# PLL0_CFG register map
Vendor: Texas Instruments
Peripheral module from a debugger description file (folder J7VCL).
Registers are 32-bit, access per field, reset 0x0 unless marked. A register's access mark holds for its fields unless they carry their own. Offsets are as the file gives them; lines under a group give offsets from that group; [hi:lo] are bit positions; {n}, {i} and the like mark numbered series; 'fields as' and 'values as' point back to an identical list; <NAME> marks a mode.

## PLL0_CFG
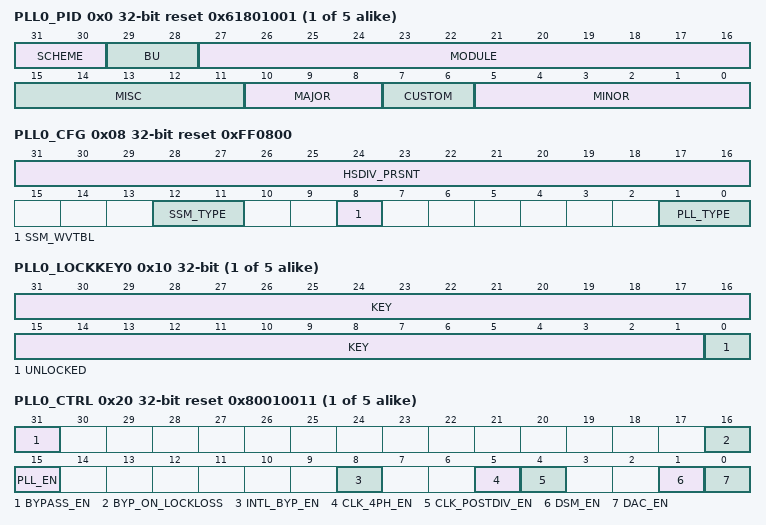
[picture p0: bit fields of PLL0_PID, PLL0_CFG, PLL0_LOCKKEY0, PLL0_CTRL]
{0x0+0x1000*i} PLL{i}_PID ro reset 0x61801001 (i=0..4) — Return to the . Peripheral Identification Register
  [31:30] SCHEME — Peripheral Identification Register Scheme
  [29:28] BU — Business Unit - Processors
  [27:16] MODULE — Module functional identifier
  [15:11] MISC — Misc revision number
  [10:8] MAJOR — Major revision number
  [7:6] CUSTOM — custom revision number
  [5:0] MINOR — Minor revision number
0x08 PLL0_CFG ro reset 0xFF0800 — Return to the . PLL MMR Configuration
  [31:16] HSDIV_PRSNT — High Speed Divider Presence Each bit Indicates the presence of High Speed dividers 0-15.By definition HSDIV[4:0] are connected the PLL FOUTVCO output clock and HSDIV[15:5] are connected to the PLL FOUTPOSTDIV output clock
  [12:11] SSM_TYPE — Spread spectrum module presence Field values (Others are reserved):2'b00 - SSM is not present 2'b01 - SSM is present 2'b10 - Reserved 2'b11 - Reserved
  [8] SSM_WVTBL — Spread spectrum wave table presence1'b0 - SSM Wave table is not present 1'b1 - SSM Wave table is present
  [1:0] PLL_TYPE — Indicates PLL type Field values (Others are reserved):2'b00 - Fractional PLL 2'b01 - FractionalF PLL 2'b10 - De-Skew PLL
{0x10+0x1000*i} PLL{i}_LOCKKEY0 (i=0..4) — Return to the . PLL{i} Lock Key 0 Register
  [31:1] KEY rw — Write the kick0 unlock value followed by the kick1 unlock value to unlock the write-protected Partition{i} registers
  [0] UNLOCKED ro — Unlock status.When set, indicates that the proper unlock sequence has been performed and the partition is unlocked for writing.
{0x14+0x1000*i} PLL{i}_LOCKKEY1 rw (i=0..4) — Return to the . PLL{i} Lock Key 1 RegisterAddr
  [31:0] LOCKKEY1_VAL — Write the kick1 unlock value after the kick0 unlock value to unlock the write-protected Partition{i} registers
{0x20+0x1000*i} PLL{i}_CTRL reset 0x80010011 (i=0..4) — Return to the . PLL{i} Control
  [31] BYPASS_EN rw — Bypass enable.This controls the glitch-free bypass mux. The bypass_en bit should be set prior tomaking any changes to the PLL settings. 1'b0 - Synchronously select PLL and associated HSDIV clock outputs 1'b1 - Synchronously select the reference clock for all PLL and HSDIV clock outputs
  [16] BYP_ON_LOCKLOSS rw — Bypass on loss of PLL lock.This bit controls the PLL bypass mux to automatically switch the clock source to the reference clock when the PLL losses lock. 1'b0 - Do not automatically switch to ref clock source on PLL lock loss 1'b1 - Switch to ref clock source when PLL losses lock
  [15] PLL_EN rw — PLL enable1'b0 - PLL is disabled 1'b1 - PLL is enabled
  [8] INTL_BYP_EN rw — PLL internal bypass enable.This is an asynchronous mux which can produce glitches on the outputclocks during switching. 1'b0 - Output clocks are derived from the VCO clock 1'b1 - Output clocks are derived from the FREF reference clock
  [5] CLK_4PH_EN rw — Enable 4-phase clock generator.This bit is ignored if clk_postdiv_en=0 1'b0 - 4-phase dividers disabled. FOUT1PHx and FOUTn clocks are held low. 1'b1 - 4-phase dividers enabled. FOUT1PH0/90/180/270 and FOUT2, FOUT3, FOUT4 clocks are enabled.
  [4] CLK_POSTDIV_EN rw — Post divide CLK enable1'b0 - Post divide powered down. FOUTPOSTDIV and all auxiliary PLL clocks (4-phase and synchronous divided clocks) are held low 1'b1 - Post divide enabled. FOUTPOSTDIV, 4-phase and synchronous clocks are enabled.
  [1] DSM_EN rw — Delta-Sigma modulator enable1'b0 - Delta-Sigma modulator is disabled (use integer divide mode) 1'b1 - Delta-Sigma modulator is enabled (use fractional divide mode)
  [0] DAC_EN rw — Enable fractional noise canceling DAC This bit has no function (DAC is always disabled) in integer divide mode (when dsm_en=0)1'b0 - Fractional NC DAC is disabled (for Test modes only) 1'b1 - Fractional NC DAC is enabled (ignored in integer divide mode)
{0x24+0x1000*i} PLL{i}_STAT ro (i=0..4) — Return to the . PLL{i} Status
  [0] LOCK — PLL lock status.Software should wait for lock to be asserted before clearing the PLL_CTRL_bypass_en bit 1'b0 - PLL is not locked 1'b1 - PLL is locked
{0x30+0x1000*i} PLL{i}_FREQ_CTRL0 reset 0x10 (i=0..4) — Return to the . PLL{i} Frequency Control {i} Register
  [11:0] FB_DIV_INT rw — PLL feedback divider (integer portion) In Integer mode values of16 - 3200 (dec) are supported. In Fractional mode values of 20 to 320 are supported. 12'h010 - Divide by 16 12'h011 - Divide by 17 : 12'h140 - Divide by 320 : 12'hC80 - Divide by 3200 12'hC81 - 12'hFFF - Not supported
{0x34+0x1000*i} PLL{i}_FREQ_CTRL1 (i=0..4) — Return to the . PLL0 Frequency Control 1 Register
  [23:0] FB_DIV_FRAC rw — PLL feedback divider (fractional portion) Supports values of 0 to 0.999999940395.The total feedback divide value is (fb_div_int + fb_div_frac / (2)) 24'h000000 - 0 24'h000001 - .000000059605 (1/(2)) 24'h000002 - .000000119209 (2/(2)) : 24'h800000 - .500000000000 : 24'hFFFFFF - .999999940395 (1677215/(2))
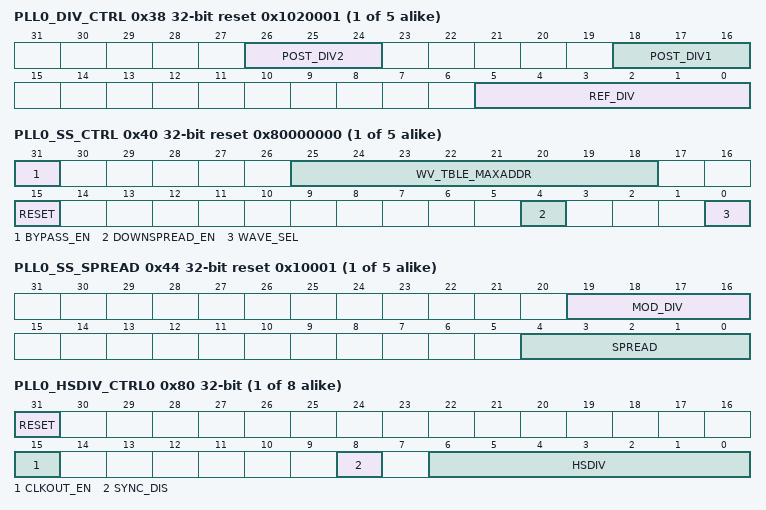
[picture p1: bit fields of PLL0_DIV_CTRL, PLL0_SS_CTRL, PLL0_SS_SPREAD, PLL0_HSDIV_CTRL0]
{0x38+0x1000*i} PLL{i}_DIV_CTRL reset 0x1020001 (i=0..4) — Return to the . PLL{i} Output Clock Divider Register
  [26:24] POST_DIV2 rw — Secondary post divider.Supports values of 1-7
  [18:16] POST_DIV1 rw — Primary post divider.To ensure correct operation, post_div1 must always be programmed to a value equal to or greater that post_div2. Supports values of 1-7i Field values (Others are reserved): 3'b000 - Reserved (do not use) 3'b001 - Divide by 1 3'b010 - Divide by 2 3'b011 - Divide by 3 3'b100 - Divide by 4 3'b101 - Divide by 5 3'b110 - Divide by 6 3'b111 - Divide by 7
  [5:0] REF_DIV rw — Reference clock pre-divider.Supports values of 1-63 6'b000000 - Reserved /(do not use/) 6'b000001 - Divide by 1 6'b000010 - Divide by 2 : 6'b111111 - Divide by 63
{0x40+0x1000*i} PLL{i}_SS_CTRL reset 0x80000000 (i=0..4) — Return to the . PLL_SS_CTRL register for PLL{i}
  [31] BYPASS_EN rw — Bypass the SS modulator.1'b0 - Spread spectrum modulation is enabled 1'b1 - SSMOD is bypassed. No modulation of PLL frequency
  [25:18] WV_TBLE_MAXADDR rw — Wave table max address.Indicates the maximum number of address bits used to access the external wave table. These bits are not used if PLL_CFG_ssm_wvtbl = 0
  [15] RESET rw — SSM reset.When set to 1 the SSM modulator is in reset
  [4] DOWNSPREAD_EN rw — Selects center spread or down spread clock variance 1'b0 - Center spread 1'b1 - Down spread
  [0] WAVE_SEL rw — Wave pattern select External wave table should only be selected if PLL_CFG_ssm_wvtbl = 1 Field values (Others are reserved):1'b0 - Use 128 point triangle wave table 1'b1 - Use external wave table
{0x44+0x1000*i} PLL{i}_SS_SPREAD reset 0x10001 (i=0..4) — Return to the . PLL_SS_SPREAD register for PLL{i}
  [19:16] MOD_DIV rw — Input clock divider.This divider sets the modulation frequency. Supports divide values of 1-63
  [4:0] SPREAD rw — Sets the spread modulation depth.The depth is spread*0.1% 5'b00000 - Reserved (don't use) 5'b00001 - 0.1% 5'b00010 - 0.2% : 5'b10000 - 1.6% : 5'b11111 - 3.1%
{0x80+4i} PLL0_HSDIV_CTRL{i} (i=0..7) — Return to the . HSDIV_CTRL{i} register for PLL0
  [31] RESET rw — SSM reset.When set to 1 the SSM modulator is in resetl
  [15] CLKOUT_EN rw — CLKOUT1 enable1'b0 - Synchronously disable CLKOUT1 1'b1 - Synchronously enable CLKOUT1
  [8] SYNC_DIS rw — Disable divider synchronization logic0 - Changes to DIV value synchronized to prevent glitches 1 - Changes are asynchronous
  [6:0] HSDIV rw — CLKOUT0 divider value (HSDIV1+1) Allowed values are 0-127
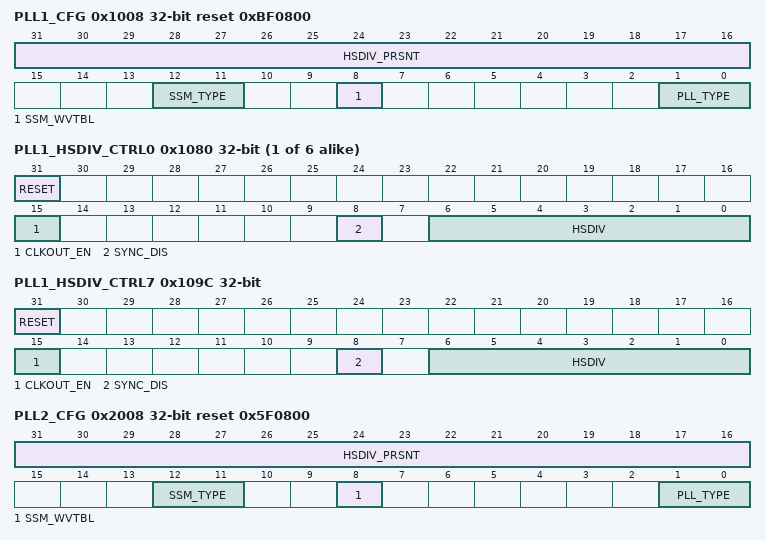
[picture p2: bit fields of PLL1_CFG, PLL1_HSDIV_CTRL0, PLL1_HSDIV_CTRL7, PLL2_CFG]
0x1008 PLL1_CFG ro reset 0xBF0800 — Return to the . PLL MMR Configuration
  fields as PLL0_CFG
{0x1080+4i} PLL1_HSDIV_CTRL{i} (i=0..5) — Return to the . HSDIV_CTRL{i} register for PLL1
  fields as PLL0_HSDIV_CTRL0
0x109C PLL1_HSDIV_CTRL7 — Return to the . HSDIV_CTRL7 register for PLL1
  fields as PLL0_HSDIV_CTRL0
0x2008 PLL2_CFG ro reset 0x5F0800 — Return to the . PLL MMR Configuration
  fields as PLL0_CFG
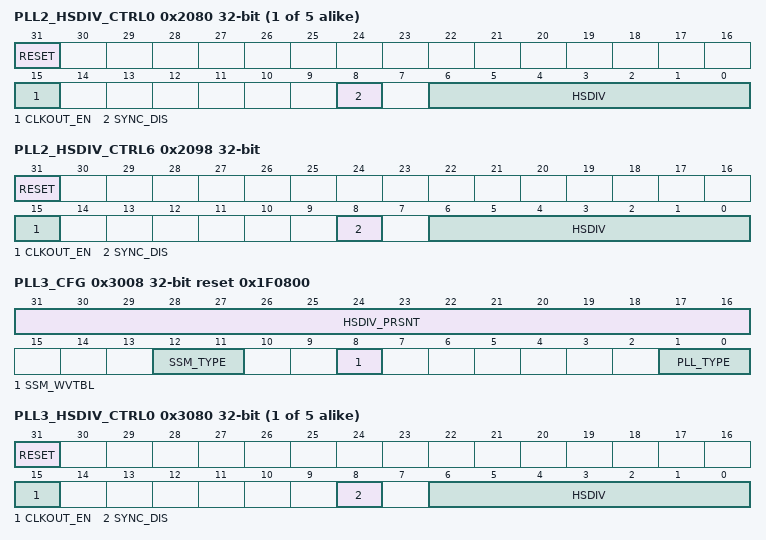
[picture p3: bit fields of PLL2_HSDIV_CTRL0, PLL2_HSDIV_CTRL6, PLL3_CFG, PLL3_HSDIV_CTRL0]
{0x2080+4i} PLL2_HSDIV_CTRL{i} (i=0..4) — Return to the . HSDIV_CTRL{i} register for PLL2
  fields as PLL0_HSDIV_CTRL0
0x2098 PLL2_HSDIV_CTRL6 — Return to the . HSDIV_CTRL6 register for PLL2
  fields as PLL0_HSDIV_CTRL0
0x3008 PLL3_CFG ro reset 0x1F0800 — Return to the . PLL MMR Configuration
  fields as PLL0_CFG
{0x3080+4i} PLL3_HSDIV_CTRL{i} (i=0..4) — Return to the . HSDIV_CTRL{i} register for PLL3
  fields as PLL0_HSDIV_CTRL0
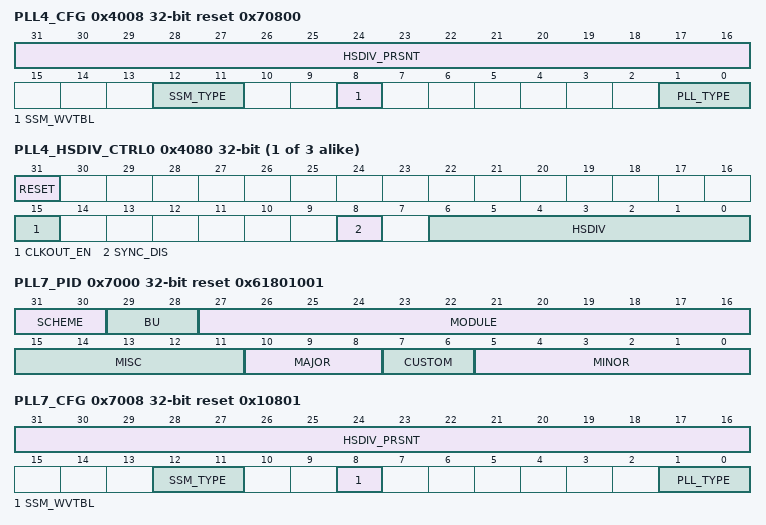
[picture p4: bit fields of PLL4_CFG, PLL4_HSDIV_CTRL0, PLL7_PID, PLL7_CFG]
0x4008 PLL4_CFG ro reset 0x70800 — Return to the . PLL MMR Configuration
  fields as PLL0_CFG
{0x4080+4i} PLL4_HSDIV_CTRL{i} (i=0..2) — Return to the . HSDIV_CTRL{i} register for PLL4
  fields as PLL0_HSDIV_CTRL0
0x7000 PLL7_PID ro reset 0x61801001 — Return to the . Peripheral Identification Register
  fields as PLL0_PID
0x7008 PLL7_CFG ro reset 0x10801 — Return to the . PLL MMR Configuration
  fields as PLL0_CFG
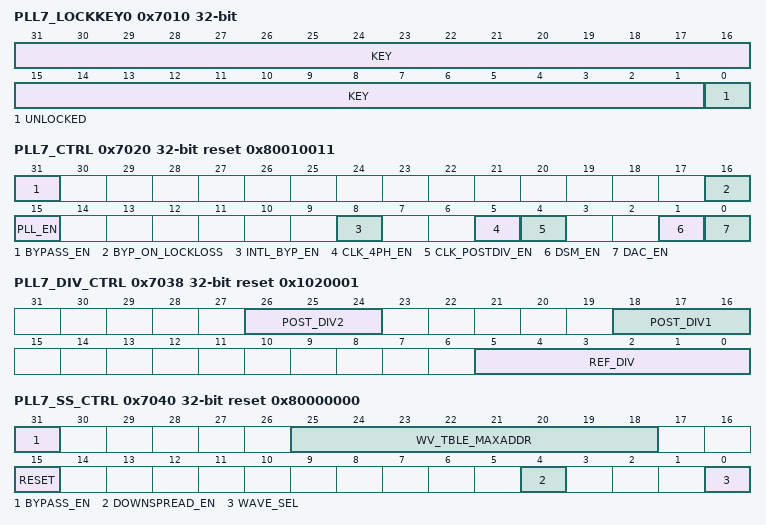
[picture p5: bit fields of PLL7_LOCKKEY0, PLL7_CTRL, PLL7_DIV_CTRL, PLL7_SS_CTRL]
0x7010 PLL7_LOCKKEY0 — Return to the . PLL7 Lock Key 0 Register
  [31:1] KEY rw — Write the kick0 unlock value followed by the kick1 unlock value to unlock the write-protected Partition7 registers
  [0] UNLOCKED ro — Unlock status.When set, indicates that the proper unlock sequence has been performed and the partition is unlocked for writing.
0x7014 PLL7_LOCKKEY1 rw — Return to the . PLL7 Lock Key 1 RegisterAddr
  [31:0] LOCKKEY1_VAL — Write the kick1 unlock value after the kick0 unlock value to unlock the write-protected Partition7 registers
0x7020 PLL7_CTRL reset 0x80010011 — Return to the . PLL7 Control
  fields as PLL0_CTRL
0x7024 PLL7_STAT ro — Return to the . PLL7 Status
  fields as PLL0_STAT
0x7030 PLL7_FREQ_CTRL0 reset 0x10 — Return to the . PLL7 Frequency Control 7 Register
  fields as PLL0_FREQ_CTRL0
0x7034 PLL7_FREQ_CTRL1 — Return to the . PLL0 Frequency Control 1 Register
  fields as PLL0_FREQ_CTRL1
0x7038 PLL7_DIV_CTRL reset 0x1020001 — Return to the . PLL7 Output Clock Divider Register
  fields as PLL0_DIV_CTRL
0x7040 PLL7_SS_CTRL reset 0x80000000 — Return to the . PLL_SS_CTRL register for PLL7
  fields as PLL0_SS_CTRL
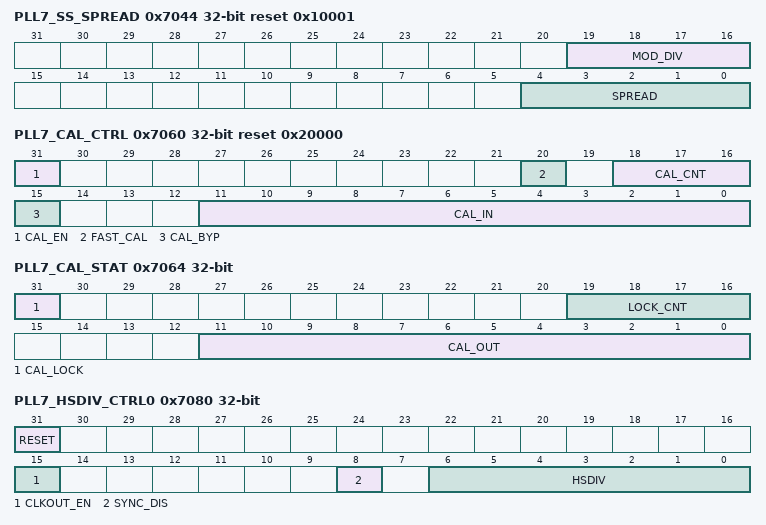
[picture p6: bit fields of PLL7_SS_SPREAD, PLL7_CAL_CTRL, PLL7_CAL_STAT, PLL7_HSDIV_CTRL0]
0x7044 PLL7_SS_SPREAD reset 0x10001 — Return to the . PLL_SS_SPREAD register for PLL7
  fields as PLL0_SS_SPREAD
0x7060 PLL7_CAL_CTRL reset 0x20000 — Return to the . PLL7 Calibration Control Register
  [31] CAL_EN rw — Calibration enable to actively adjust for input skew1'b0 - Disabled. Static phase offset determined by analog matching only 1'b1 - Enabled. Static phase offset adjusted by phase sensing at input
  [20] FAST_CAL rw — Fast calibration enabled1'b0 - Normal operation 1'b1 - Used for initial calibration if initial value is not already known
  [18:16] CAL_CNT rw — Calibration loop programmable counter.Selects the number of PFD edges to wait after each calibration step defined by 2**cal_cnt
  [15] CAL_BYP rw — Calibration bypass1'b0 - Use the calibration output to set the phase correction 1'b1 - Use the cal_in input value to set the phase correction
  [11:0] CAL_IN rw — Calibration input When cal_byp is 1'b0, this represents the initial condition for calibration.When cal_byp is 1'b1, this is the override value for calibration. Value is a signed integer with positive values delaying the faster path reset and negative values delaying the slower path reset.
0x7064 PLL7_CAL_STAT ro — Return to the . PLL7 Calibration Status Register
  [31] CAL_LOCK — Reserved for future use
  [19:16] LOCK_CNT — Reserved for future use
  [11:0] CAL_OUT — Output of the calibration block if cal_byp = 1'b0.If cal_byp = 1'b1 it is a buffer version of cal_in[11:0]. Can be used to read the phase calibration state to for later use as an override value to bypass skew calibration
0x7080 PLL7_HSDIV_CTRL0 — Return to the . HSDIV_CTRL0 register for PLL7
  fields as PLL0_HSDIV_CTRL0
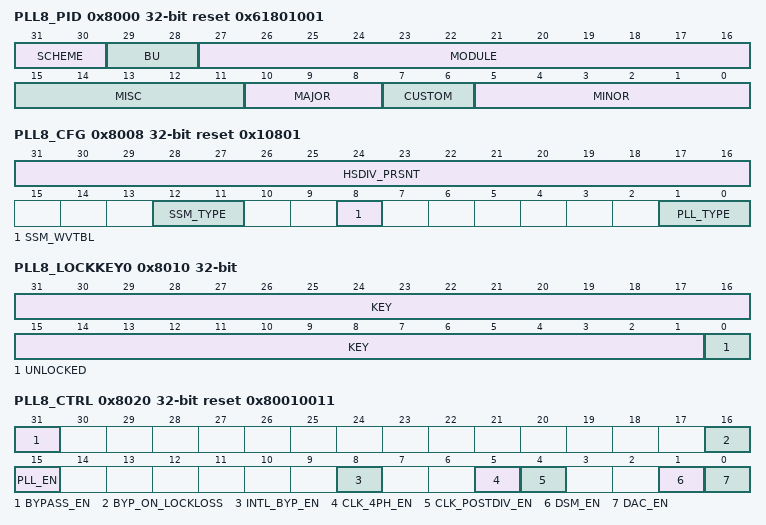
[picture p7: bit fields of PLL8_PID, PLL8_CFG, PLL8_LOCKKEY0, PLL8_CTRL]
0x8000 PLL8_PID ro reset 0x61801001 — Return to the . Peripheral Identification Register
  fields as PLL0_PID
0x8008 PLL8_CFG ro reset 0x10801 — Return to the . PLL MMR Configuration
  fields as PLL0_CFG
0x8010 PLL8_LOCKKEY0 — Return to the . PLL8 Lock Key 0 Register
  [31:1] KEY rw — Write the kick0 unlock value followed by the kick1 unlock value to unlock the write-protected Partition8 registers
  [0] UNLOCKED ro — Unlock status.When set, indicates that the proper unlock sequence has been performed and the partition is unlocked for writing.
0x8014 PLL8_LOCKKEY1 rw — Return to the . PLL8 Lock Key 1 RegisterAddr
  [31:0] LOCKKEY1_VAL — Write the kick1 unlock value after the kick0 unlock value to unlock the write-protected Partition8 registers
0x8020 PLL8_CTRL reset 0x80010011 — Return to the . PLL8 Control
  fields as PLL0_CTRL
0x8024 PLL8_STAT ro — Return to the . PLL8 Status
  fields as PLL0_STAT
0x8030 PLL8_FREQ_CTRL0 reset 0x10 — Return to the . PLL8 Frequency Control 8 Register
  fields as PLL0_FREQ_CTRL0
0x8034 PLL8_FREQ_CTRL1 — Return to the . PLL0 Frequency Control 1 Register
  fields as PLL0_FREQ_CTRL1
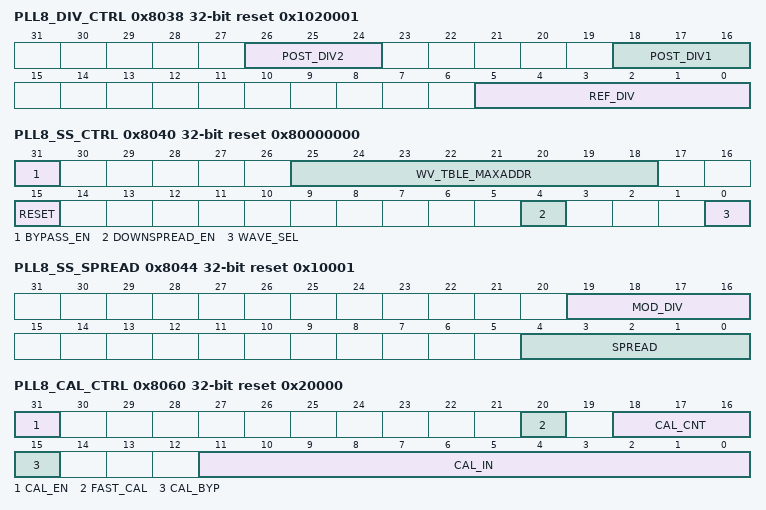
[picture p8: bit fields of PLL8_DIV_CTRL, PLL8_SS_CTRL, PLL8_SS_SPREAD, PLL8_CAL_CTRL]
0x8038 PLL8_DIV_CTRL reset 0x1020001 — Return to the . PLL8 Output Clock Divider Register
  fields as PLL0_DIV_CTRL
0x8040 PLL8_SS_CTRL reset 0x80000000 — Return to the . PLL_SS_CTRL register for PLL8
  fields as PLL0_SS_CTRL
0x8044 PLL8_SS_SPREAD reset 0x10001 — Return to the . PLL_SS_SPREAD register for PLL8
  fields as PLL0_SS_SPREAD
0x8060 PLL8_CAL_CTRL reset 0x20000 — Return to the . PLL8 Calibration Control Register
  fields as PLL7_CAL_CTRL
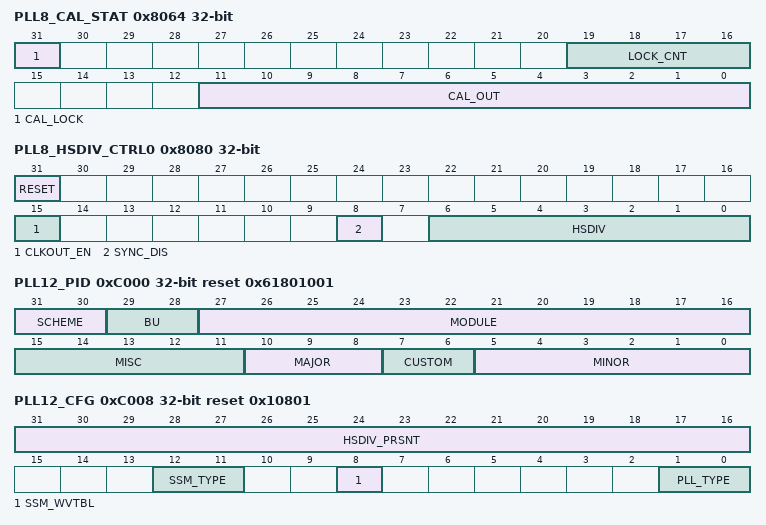
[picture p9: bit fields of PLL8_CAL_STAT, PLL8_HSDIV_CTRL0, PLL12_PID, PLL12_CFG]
0x8064 PLL8_CAL_STAT ro — Return to the . PLL8 Calibration Status Register
  fields as PLL7_CAL_STAT
0x8080 PLL8_HSDIV_CTRL0 — Return to the . HSDIV_CTRL0 register for PLL8
  fields as PLL0_HSDIV_CTRL0
0xC000 PLL12_PID ro reset 0x61801001 — Return to the . Peripheral Identification Register
  fields as PLL0_PID
0xC008 PLL12_CFG ro reset 0x10801 — Return to the . PLL MMR Configuration
  fields as PLL0_CFG
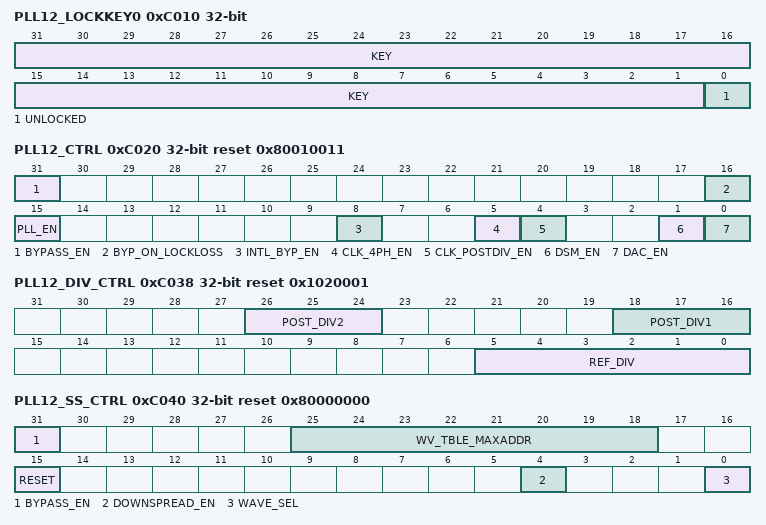
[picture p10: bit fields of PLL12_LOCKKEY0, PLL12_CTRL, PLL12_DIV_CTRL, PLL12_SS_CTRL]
0xC010 PLL12_LOCKKEY0 — Return to the . PLL12 Lock Key 0 Register
  [31:1] KEY rw — Write the kick0 unlock value followed by the kick1 unlock value to unlock the write-protected Partition12 registers
  [0] UNLOCKED ro — Unlock status.When set, indicates that the proper unlock sequence has been performed and the partition is unlocked for writing.
0xC014 PLL12_LOCKKEY1 rw — Return to the . PLL12 Lock Key 1 RegisterAddr
  [31:0] LOCKKEY1_VAL — Write the kick1 unlock value after the kick0 unlock value to unlock the write-protected Partition12 registers
0xC020 PLL12_CTRL reset 0x80010011 — Return to the . PLL12 Control
  fields as PLL0_CTRL
0xC024 PLL12_STAT ro — Return to the . PLL12 Status
  fields as PLL0_STAT
0xC030 PLL12_FREQ_CTRL0 reset 0x10 — Return to the . PLL12 Frequency Control 12 Register
  fields as PLL0_FREQ_CTRL0
0xC034 PLL12_FREQ_CTRL1 — Return to the . PLL0 Frequency Control 1 Register
  fields as PLL0_FREQ_CTRL1
0xC038 PLL12_DIV_CTRL reset 0x1020001 — Return to the . PLL12 Output Clock Divider Register
  fields as PLL0_DIV_CTRL
0xC040 PLL12_SS_CTRL reset 0x80000000 — Return to the . PLL_SS_CTRL register for PLL12
  fields as PLL0_SS_CTRL
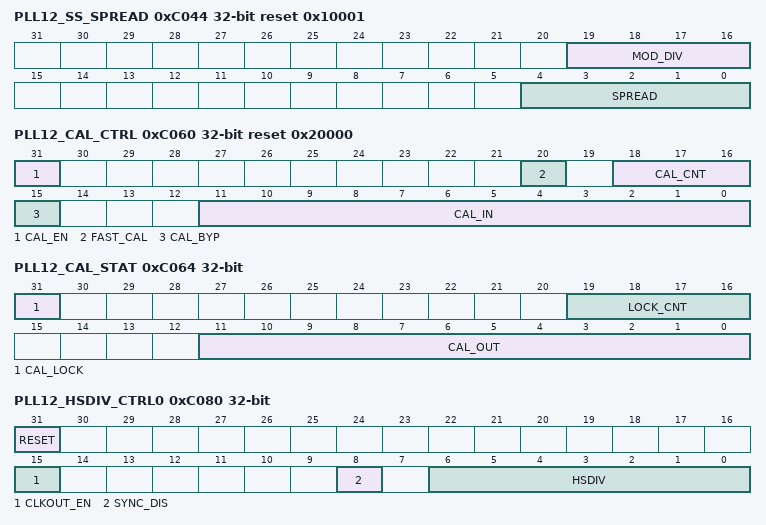
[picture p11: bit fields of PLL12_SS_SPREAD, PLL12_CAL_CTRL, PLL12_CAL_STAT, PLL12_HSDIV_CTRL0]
0xC044 PLL12_SS_SPREAD reset 0x10001 — Return to the . PLL_SS_SPREAD register for PLL12
  fields as PLL0_SS_SPREAD
0xC060 PLL12_CAL_CTRL reset 0x20000 — Return to the . PLL12 Calibration Control Register
  fields as PLL7_CAL_CTRL
0xC064 PLL12_CAL_STAT ro — Return to the . PLL12 Calibration Status Register
  fields as PLL7_CAL_STAT
0xC080 PLL12_HSDIV_CTRL0 — Return to the . HSDIV_CTRL0 register for PLL12
  fields as PLL0_HSDIV_CTRL0
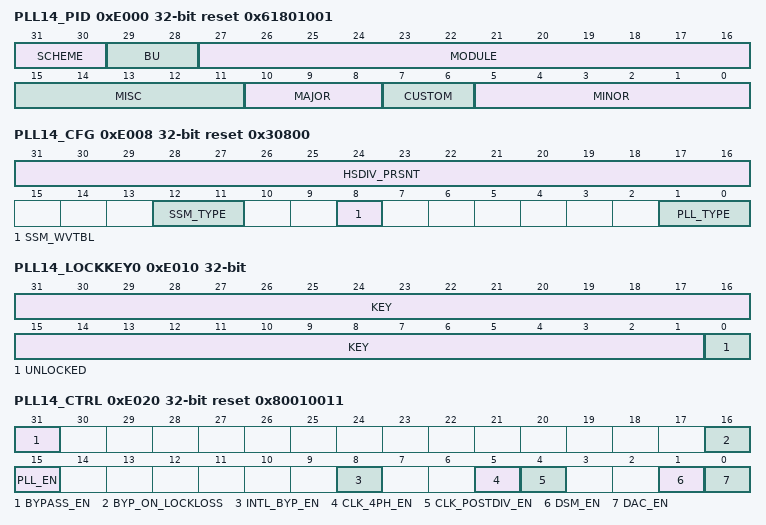
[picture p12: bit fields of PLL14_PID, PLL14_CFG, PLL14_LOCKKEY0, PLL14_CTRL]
0xE000 PLL14_PID ro reset 0x61801001 — Return to the . Peripheral Identification Register
  fields as PLL0_PID
0xE008 PLL14_CFG ro reset 0x30800 — Return to the . PLL MMR Configuration
  fields as PLL0_CFG
0xE010 PLL14_LOCKKEY0 — Return to the . PLL14 Lock Key 0 Register
  [31:1] KEY rw — Write the kick0 unlock value followed by the kick1 unlock value to unlock the write-protected Partition14 registers
  [0] UNLOCKED ro — Unlock status.When set, indicates that the proper unlock sequence has been performed and the partition is unlocked for writing.
0xE014 PLL14_LOCKKEY1 rw — Return to the . PLL14 Lock Key 1 RegisterAddr
  [31:0] LOCKKEY1_VAL — Write the kick1 unlock value after the kick0 unlock value to unlock the write-protected Partition14 registers
0xE020 PLL14_CTRL reset 0x80010011 — Return to the . PLL14 Control
  fields as PLL0_CTRL
0xE024 PLL14_STAT ro — Return to the . PLL14 Status
  fields as PLL0_STAT
0xE030 PLL14_FREQ_CTRL0 reset 0x10 — Return to the . PLL14 Frequency Control 14 Register
  fields as PLL0_FREQ_CTRL0
0xE034 PLL14_FREQ_CTRL1 — Return to the . PLL0 Frequency Control 1 Register
  fields as PLL0_FREQ_CTRL1
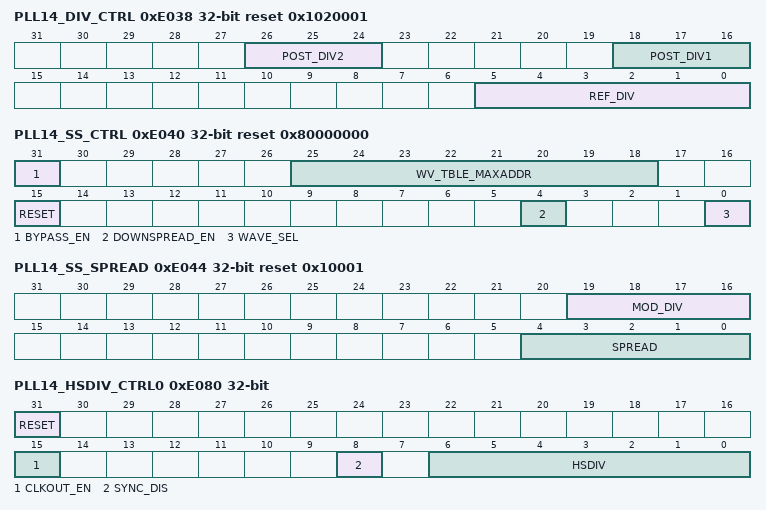
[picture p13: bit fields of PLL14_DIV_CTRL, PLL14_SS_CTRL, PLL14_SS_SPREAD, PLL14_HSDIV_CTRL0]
0xE038 PLL14_DIV_CTRL reset 0x1020001 — Return to the . PLL14 Output Clock Divider Register
  fields as PLL0_DIV_CTRL
0xE040 PLL14_SS_CTRL reset 0x80000000 — Return to the . PLL_SS_CTRL register for PLL14
  fields as PLL0_SS_CTRL
0xE044 PLL14_SS_SPREAD reset 0x10001 — Return to the . PLL_SS_SPREAD register for PLL14
  fields as PLL0_SS_SPREAD
0xE080 PLL14_HSDIV_CTRL0 — Return to the . HSDIV_CTRL0 register for PLL14
  fields as PLL0_HSDIV_CTRL0
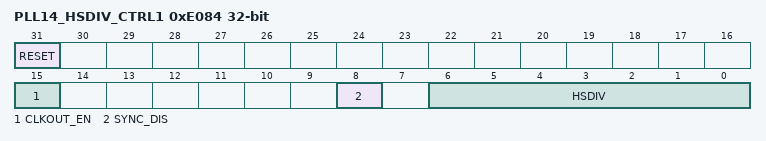
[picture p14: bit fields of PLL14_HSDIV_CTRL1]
0xE084 PLL14_HSDIV_CTRL1 — Return to the . HSDIV_CTRL1 register for PLL14
  fields as PLL0_HSDIV_CTRL0
